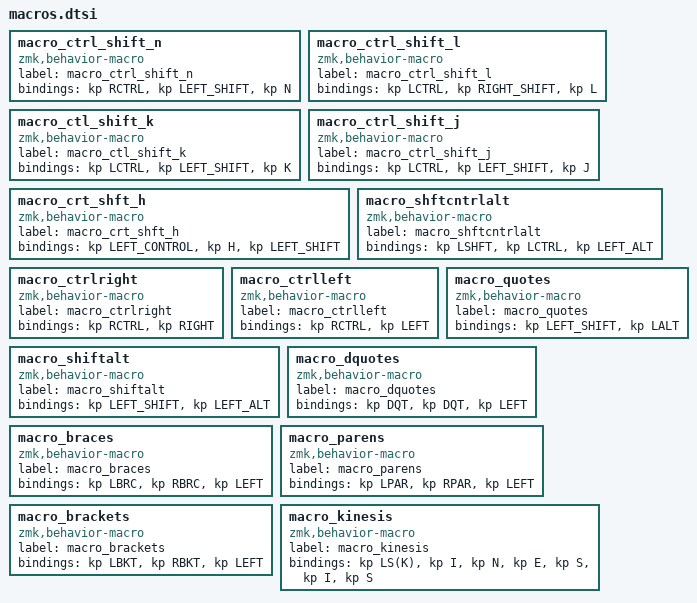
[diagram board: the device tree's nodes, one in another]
macro_ctrl_shift_n: macro_ctrl_shift_n{
compatible = "zmk,behavior-macro";
label = "macro_ctrl_shift_n";
#binding-cells = <0>;
bindings = <&kp RCTRL>, <&kp LEFT_SHIFT>, <&kp N>;
};
macro_ctrl_shift_l: macro_ctrl_shift_l{
compatible = "zmk,behavior-macro";
label = "macro_ctrl_shift_l";
#binding-cells = <0>;
bindings = <&kp LCTRL>, <&kp RIGHT_SHIFT>, <&kp L>;
};
macro_ctl_shift_k: macro_ctl_shift_k{
compatible = "zmk,behavior-macro";
label = "macro_ctl_shift_k";
#binding-cells = <0>;
bindings = <&kp LCTRL>, <&kp LEFT_SHIFT>, <&kp K>;
};
macro_ctrl_shift_j: macro_ctrl_shift_j{
compatible = "zmk,behavior-macro";
label = "macro_ctrl_shift_j";
#binding-cells = <0>;
bindings = <&kp LCTRL>, <&kp LEFT_SHIFT>, <&kp J>;
};
macro_crt_shft_h: macro_crt_shft_h{
compatible = "zmk,behavior-macro";
label = "macro_crt_shft_h";
#binding-cells = <0>;
bindings = <&kp LEFT_CONTROL>, <&kp H>, <&kp LEFT_SHIFT>;
};
macro_shftcntrlalt: macro_shftcntrlalt{
compatible = "zmk,behavior-macro";
label = "macro_shftcntrlalt";
#binding-cells = <0>;
bindings = <&kp LSHFT>, <&kp LCTRL>, <&kp LEFT_ALT>;
};
macro_ctrlright: macro_ctrlright{
compatible = "zmk,behavior-macro";
label = "macro_ctrlright";
#binding-cells = <0>;
bindings = <&kp RCTRL>, <&kp RIGHT>;
};
macro_ctrlleft: macro_ctrlleft{
compatible = "zmk,behavior-macro";
label = "macro_ctrlleft";
#binding-cells = <0>;
bindings = <&kp RCTRL>, <&kp LEFT>;
};
macro_shiftalt: macro_shiftalt{
compatible = "zmk,behavior-macro";
label = "macro_shiftalt";
#binding-cells = <0>;
bindings = <&kp LEFT_SHIFT>, <&kp LEFT_ALT>;
};
macro_quotes: macro_quotes{
compatible = "zmk,behavior-macro";
label = "macro_quotes";
#binding-cells = <0>;
bindings = <&kp LEFT_SHIFT>, <&kp LALT>;
};
macro_dquotes: macro_dquotes{
compatible = "zmk,behavior-macro";
label = "macro_dquotes";
#binding-cells = <0>;
bindings = <&kp DQT>, <&kp DQT>, <&kp LEFT>;
};
macro_braces: macro_braces{
compatible = "zmk,behavior-macro";
label = "macro_braces";
#binding-cells = <0>;
bindings = <&kp LBRC>, <&kp RBRC>, <&kp LEFT>;
};
macro_parens: macro_parens{
compatible = "zmk,behavior-macro";
label = "macro_parens";
#binding-cells = <0>;
bindings = <&kp LPAR>, <&kp RPAR>, <&kp LEFT>;
};
macro_brackets: macro_brackets{
compatible = "zmk,behavior-macro";
label = "macro_brackets";
#binding-cells = <0>;
bindings = <&kp LBKT>, <&kp RBKT>, <&kp LEFT>;
};
macro_kinesis: macro_kinesis{
compatible = "zmk,behavior-macro";
label = "macro_kinesis";
#binding-cells = <0>;
bindings = <&kp LS(K)>, <&kp I>, <&kp N>, <&kp E>, <&kp S>, <&kp I>, <&kp S>;
};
